# ADSP-2183xW_LPC register map
Vendor: Analog Devices; Series: ADSP-2183xW_LPC; File version: 3.0.3.517
CPU: 
Registers are 32-bit, read-write, reset 0x0 unless marked. A register's access mark holds for its fields unless they carry their own. Offsets are from the block's base; [hi:lo] are bit positions; {n}, {i} and the like mark numbered series; 'fields as' and 'values as' point back to an identical list.

## SOC600CTI_TRACE4
Base 0x3110C000
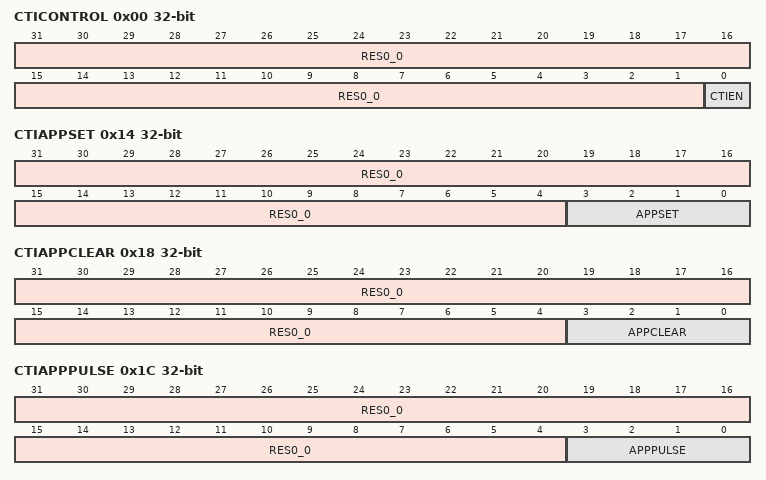
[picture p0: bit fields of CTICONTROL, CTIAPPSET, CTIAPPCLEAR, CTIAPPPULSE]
0x00 CTICONTROL
  [31:1] RES0_0 range 0x00000000..0x7FFFFFFF, [0] CTIEN range 0x00000000..0x00000001
0x10 CTIINTACK — CTI Interrupt Acknowledge register.
  [31:0] INTACK wo range 0x00000000..0xFFFFFFFF
0x14 CTIAPPSET — CTI Application Channel Set register.
  [31:4] RES0_0 range 0x00000000..0x0FFFFFFF, [3:0] APPSET range 0x00000000..0x0000000F
0x18 CTIAPPCLEAR — CTI Application Channel Clear register.
  [31:4] RES0_0 wo range 0x00000000..0x0FFFFFFF, [3:0] APPCLEAR wo range 0x00000000..0x0000000F
0x1C CTIAPPPULSE — CTI Application Channel Pulse register.
  [31:4] RES0_0 wo range 0x00000000..0x0FFFFFFF, [3:0] APPPULSE wo range 0x00000000..0x0000000F
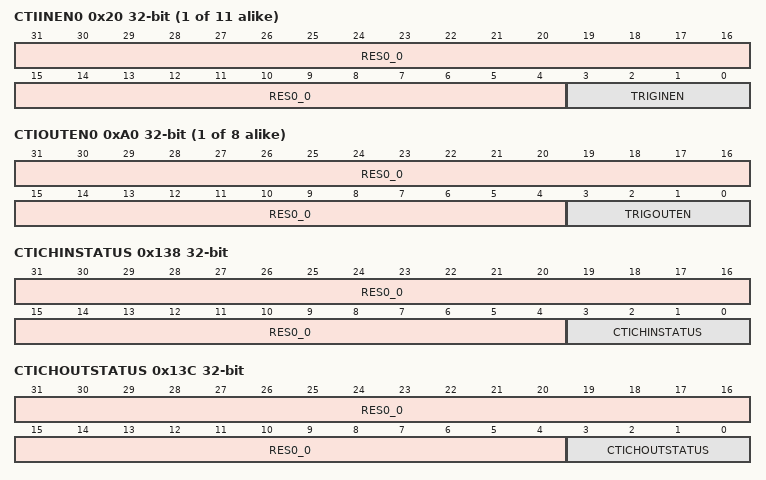
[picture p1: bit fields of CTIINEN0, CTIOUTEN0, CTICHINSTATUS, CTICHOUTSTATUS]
{0x20+4i} CTIINEN{i} (i=0..10) — CTI Trigger {i} to Channel Enable register.
  [31:4] RES0_0 range 0x00000000..0x0FFFFFFF, [3:0] TRIGINEN range 0x00000000..0x0000000F
{0xA0+4i} CTIOUTEN{i} (i=0..7) — CTI Channel to Trigger {i} Enable register.
  [31:4] RES0_0 range 0x00000000..0x0FFFFFFF, [3:0] TRIGOUTEN range 0x00000000..0x0000000F
0x130 CTITRIGINSTATUS — CTI Trigger Input Status register.
  [31:0] TRIGINSTATUS ro
0x134 CTITRIGOUTSTATUS — CTI Trigger Output Status register.
  [31:0] TRIGOUTSTATUS ro
0x138 CTICHINSTATUS — CTI Channel Input Status register.
  [31:4] RES0_0 ro, [3:0] CTICHINSTATUS ro
0x13C CTICHOUTSTATUS — CTI Channel Output Status register.
  [31:4] RES0_0 ro, [3:0] CTICHOUTSTATUS ro
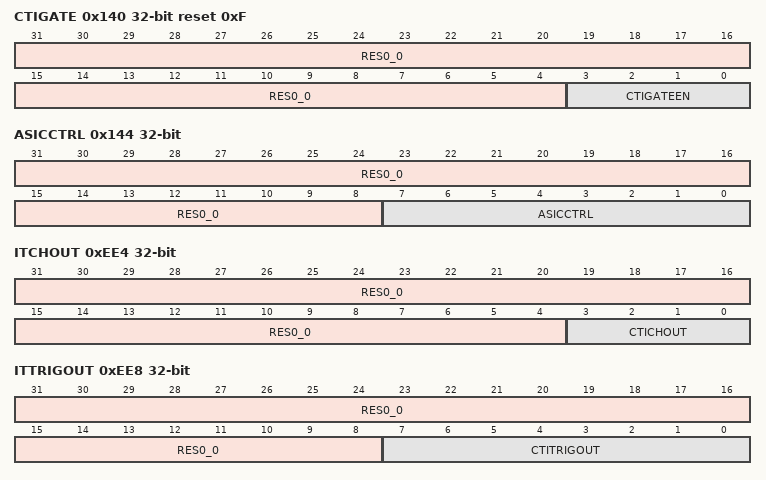
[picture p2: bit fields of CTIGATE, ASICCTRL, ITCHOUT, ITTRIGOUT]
0x140 CTIGATE reset 0xF — Enable CTI Channel Gate register.
  [31:4] RES0_0 range 0x00000000..0x0FFFFFFF, [3:0] CTIGATEEN range 0x00000000..0x0000000F
0x144 ASICCTRL — External Multiplexer Control register.
  [31:8] RES0_0 range 0x00000000..0x00FFFFFF, [7:0] ASICCTRL range 0x00000000..0x000000FF
0xEE4 ITCHOUT — Integration Test Channel Output register.
  [31:4] RES0_0 range 0x00000000..0x0FFFFFFF, [3:0] CTICHOUT wo range 0x00000000..0x0000000F
0xEE8 ITTRIGOUT — Integration Test Trigger Output register.
  [31:8] RES0_0 range 0x00000000..0x00FFFFFF, [7:0] CTITRIGOUT range 0x00000000..0x000000FF
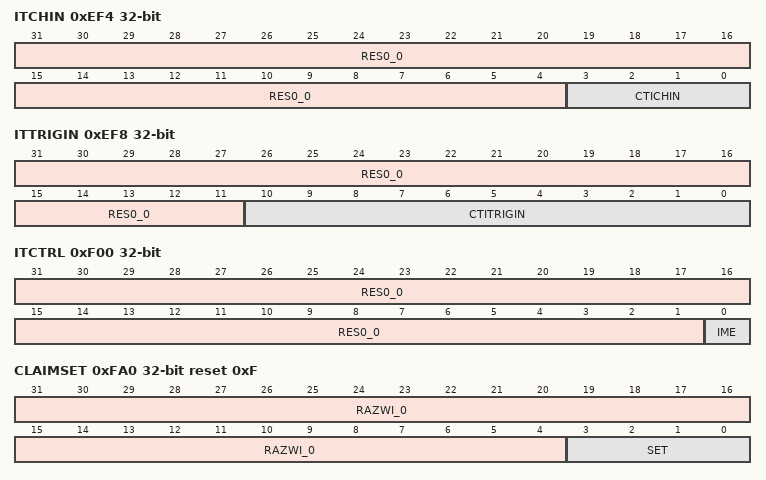
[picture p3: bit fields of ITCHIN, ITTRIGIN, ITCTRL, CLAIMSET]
0xEF4 ITCHIN — Integration Test Channel Input register.
  [31:4] RES0_0 ro, [3:0] CTICHIN ro
0xEF8 ITTRIGIN — Integration Test Trigger Input register.
  [31:11] RES0_0 ro, [10:0] CTITRIGIN ro
0xF00 ITCTRL — Integration Mode Control Register.
  [31:1] RES0_0 range 0x00000000..0x7FFFFFFF, [0] IME range 0x00000000..0x00000001
0xFA0 CLAIMSET reset 0xF — Claim Tag Set Register.
  [31:4] RAZWI_0 range 0x00000000..0x0FFFFFFF, [3:0] SET range 0x00000000..0x0000000F
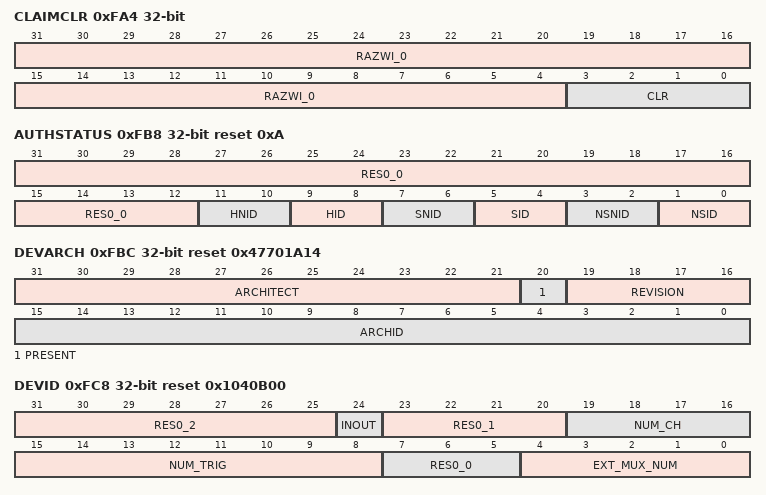
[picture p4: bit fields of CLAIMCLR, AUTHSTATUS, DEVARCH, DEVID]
0xFA4 CLAIMCLR — Claim Tag Clear Register.
  [31:4] RAZWI_0 range 0x00000000..0x0FFFFFFF, [3:0] CLR range 0x00000000..0x0000000F
0xFA8 DEVAFF0 reset 0xFFFFFFFF — Device Affinity register 0.
  [31:0] DEVAFF0 ro
0xFAC DEVAFF1 reset 0xFFFFFFFF — Device Affinity register 1.
  [31:0] DEVAFF1 ro
0xFB8 AUTHSTATUS reset 0xA — Authentication Status Register.
  [31:12] RES0_0 ro, [11:10] HNID ro, [9:8] HID ro, [7:6] SNID ro, [5:4] SID ro, [3:2] NSNID ro, [1:0] NSID ro
0xFBC DEVARCH reset 0x47701A14 — Device Architecture Register.
  [31:21] ARCHITECT ro, [20] PRESENT ro, [19:16] REVISION ro, [15:0] ARCHID ro
0xFC8 DEVID reset 0x1040B00 — Device Configuration Register.
  [31:25] RES0_2 ro, [24] INOUT ro, [23:20] RES0_1 ro, [19:16] NUM_CH ro, [15:8] NUM_TRIG ro, [7:5] RES0_0 ro, [4:0] EXT_MUX_NUM ro
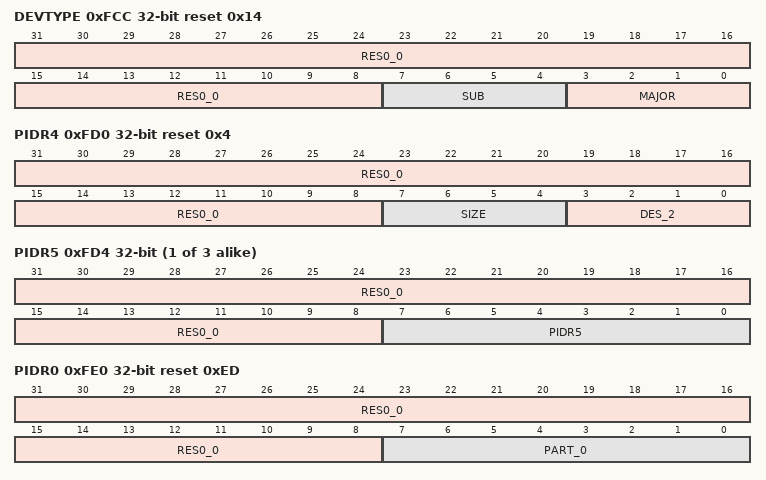
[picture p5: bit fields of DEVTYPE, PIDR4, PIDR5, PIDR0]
0xFCC DEVTYPE reset 0x14 — Device Type Identifier Register.
  [31:8] RES0_0 ro, [7:4] SUB ro, [3:0] MAJOR ro
0xFD0 PIDR4 reset 0x4 — Peripheral Identification Register 4.
  [31:8] RES0_0 ro, [7:4] SIZE ro, [3:0] DES_2 ro
{0xFC0+4i} PIDR{i} (i=5..7) — Peripheral Identification Register {i}.
  [31:8] RES0_0 ro, [7:0] PIDR{i} ro
0xFE0 PIDR0 reset 0xED — Peripheral Identification Register 0.
  [31:8] RES0_0 ro, [7:0] PART_0 ro
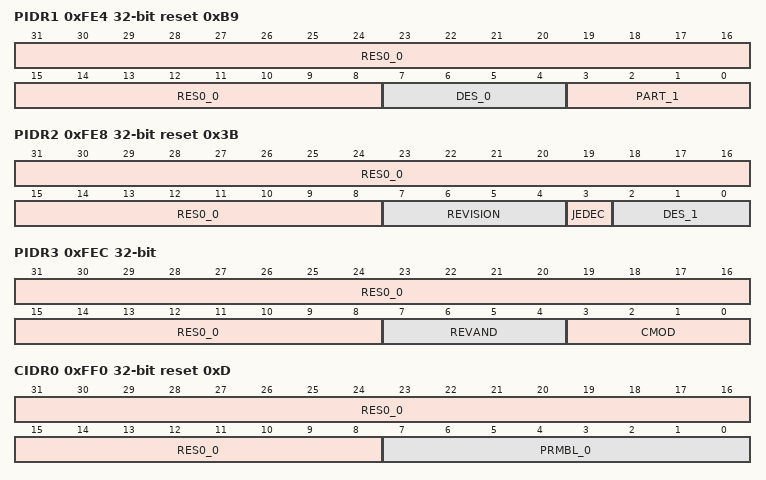
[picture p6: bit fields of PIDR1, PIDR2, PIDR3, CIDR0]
0xFE4 PIDR1 reset 0xB9 — Peripheral Identification Register 1.
  [31:8] RES0_0 ro, [7:4] DES_0 ro, [3:0] PART_1 ro
0xFE8 PIDR2 reset 0x3B — Peripheral Identification Register 2.
  [31:8] RES0_0 ro, [7:4] REVISION ro, [3] JEDEC ro, [2:0] DES_1 ro
0xFEC PIDR3 — Peripheral Identification Register 3.
  [31:8] RES0_0 ro, [7:4] REVAND ro, [3:0] CMOD ro
0xFF0 CIDR0 reset 0xD — Component Identification Register 0.
  [31:8] RES0_0 ro, [7:0] PRMBL_0 ro
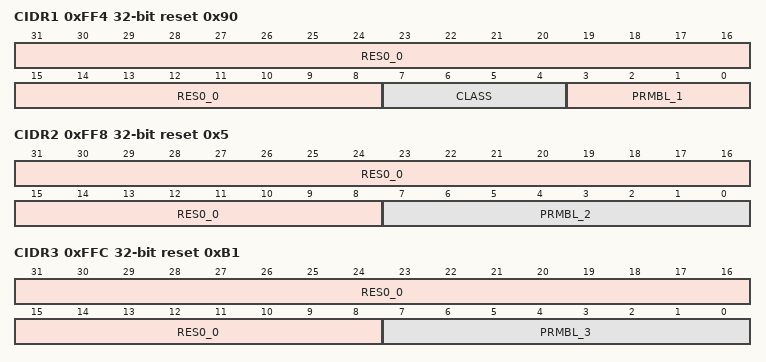
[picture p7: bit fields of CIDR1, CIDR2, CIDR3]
0xFF4 CIDR1 reset 0x90 — Component Identification Register 1.
  [31:8] RES0_0 ro, [7:4] CLASS ro, [3:0] PRMBL_1 ro
0xFF8 CIDR2 reset 0x5 — Component Identification Register 2.
  [31:8] RES0_0 ro, [7:0] PRMBL_2 ro
0xFFC CIDR3 reset 0xB1 — Component Identification Register 3.
  [31:8] RES0_0 ro, [7:0] PRMBL_3 ro

## SOC600CTI_SYS3
Base 0x3110D000
Registers as SOC600CTI_TRACE4, without CTIINEN{n} (n=8..10); these are added or differ:
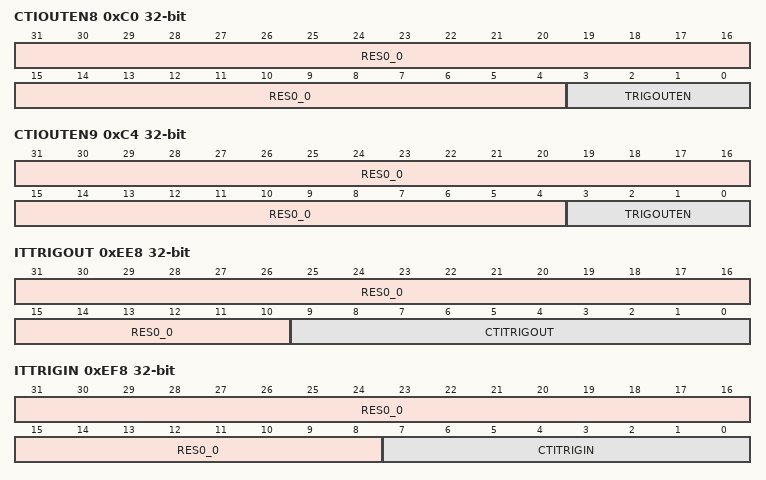
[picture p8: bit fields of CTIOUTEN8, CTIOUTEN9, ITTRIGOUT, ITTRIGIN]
0xC0 CTIOUTEN8 — CTI Channel to Trigger 8 Enable register.
  [31:4] RES0_0 range 0x00000000..0x0FFFFFFF, [3:0] TRIGOUTEN range 0x00000000..0x0000000F
0xC4 CTIOUTEN9 — CTI Channel to Trigger 9 Enable register.
  fields as CTIOUTEN8
0xEE8 ITTRIGOUT — Integration Test Trigger Output register.
  [31:10] RES0_0 range 0x00000000..0x003FFFFF, [9:0] CTITRIGOUT range 0x00000000..0x000003FF
0xEF8 ITTRIGIN — Integration Test Trigger Input register.
  [31:8] RES0_0 ro, [7:0] CTITRIGIN ro
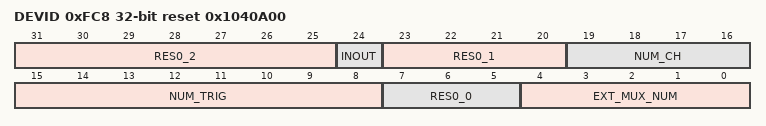
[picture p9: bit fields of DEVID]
0xFC8 DEVID reset 0x1040A00 — Device Configuration Register.
  [31:25] RES0_2 ro, [24] INOUT ro, [23:20] RES0_1 ro, [19:16] NUM_CH ro, [15:8] NUM_TRIG ro, [7:5] RES0_0 ro, [4:0] EXT_MUX_NUM ro
